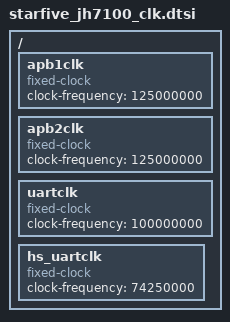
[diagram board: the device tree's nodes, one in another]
/*
 * Copyright (C) 2021 StarFive, Inc.
 *
 * SPDX-License-Identifier: Apache-2.0
 */

/ {
	apb1clk: apb1clk {
		compatible = "fixed-clock";
		#clock-cells = <0>;
		clock-frequency = <125000000>;
	};

	apb2clk: apb2clk {
		compatible = "fixed-clock";
		#clock-cells = <0>;
		clock-frequency = <125000000>;
	};

	uartclk: uartclk {
		compatible = "fixed-clock";
		#clock-cells = <0>;
		clock-frequency = <100000000>;
	};

	hs_uartclk: hs_uartclk {
		compatible = "fixed-clock";
		#clock-cells = <0>;
		clock-frequency = <74250000>;
	};
};
